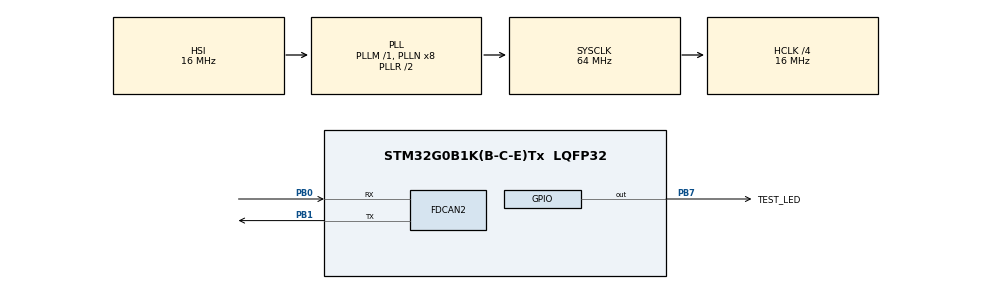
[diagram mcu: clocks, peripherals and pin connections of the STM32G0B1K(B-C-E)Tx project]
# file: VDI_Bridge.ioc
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FDCAN2.AutoRetransmission=DISABLE
FDCAN2.CalculateBaudRateNominal=500000
FDCAN2.CalculateTimeBitNominal=2000
FDCAN2.CalculateTimeQuantumNominal=125.0
FDCAN2.FrameFormat=FDCAN_FRAME_CLASSIC
FDCAN2.NominalPrescaler=2
FDCAN2.NominalTimeSeg1=13
FDCAN2.NominalTimeSeg2=2
Mcu.Family=STM32G0
Mcu.Name=STM32G0B1K(B-C-E)Tx
Mcu.Package=LQFP32
NVIC.TIM16_FDCAN_IT0_IRQn=true\:0\:0\:false\:false\:true\:true\:true\:true
NVIC.TIM1_BRK_UP_TRG_COM_IRQn=true\:0\:0\:false\:false\:true\:true\:true\:true
PA13.Mode=Serial_Wire
PA13.Signal=SYS_SWDIO
PA14-BOOT0.Mode=Serial_Wire
PA14-BOOT0.Signal=SYS_SWCLK
PB0.Mode=FDCAN_Activate
PB0.Signal=FDCAN2_RX
PB1.Mode=FDCAN_Activate
PB1.Signal=FDCAN2_TX
PB7.GPIO_Label=TEST_LED
PB7.Signal=GPIO_Output
ProjectManager.HeapSize=0x200
ProjectManager.StackSize=0x400
ProjectManager.TargetToolchain=STM32CubeIDE
RCC.ADCFreq_Value=64000000
RCC.AHBCLKDivider=RCC_SYSCLK_DIV4
RCC.AHBFreq_Value=16000000
RCC.CortexFreq_Value=16000000
RCC.EXTERNAL_CLOCK_VALUE=48000
RCC.HCLKFreq_Value=16000000
RCC.HSE_VALUE=8000000
RCC.HSI48_VALUE=48000000
RCC.HSI_VALUE=16000000
RCC.LSE_VALUE=32768
RCC.SYSCLKFreq_VALUE=64000000
RCC.SYSCLKSource=RCC_SYSCLKSOURCE_PLLCLK
RCC.USBFreq_Value=48000000
RCC.VCOOutputFreq_Value=128000000
TIM1.Period=100-1
TIM1.Prescaler=16000-1
VP_SYS_VS_DBSignals.Mode=DisableDeadBatterySignals
VP_TIM1_VS_ClockSourceINT.Mode=Internal
board=custom

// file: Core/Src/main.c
/* USER CODE BEGIN Header */
/**
 ******************************************************************************
 * @file           : main.c
 * @brief          : Main program body
 ******************************************************************************
 * @attention
 *
 * Copyright (c) 2024 STMicroelectronics.
 * All rights reserved.
 *
 * This software is licensed under terms that can be found in the LICENSE file
 * in the root directory of this software component.
 * If no LICENSE file comes with this software, it is provided AS-IS.
 *
 ******************************************************************************
 */
/* USER CODE END Header */
#include "main.h"

FDCAN_HandleTypeDef hfdcan2;

TIM_HandleTypeDef htim1;

/* USER CODE BEGIN PV */
uint8_t TxData[CAN_SIZE];
uint8_t TxDataBEAT[CAN_SIZE];
uint8_t TxDataSTART[CAN_SIZE];

uint8_t RxData[CAN_SIZE];
uint32_t TxMailbox;
FDCAN_TxHeaderTypeDef TxHeader;
FDCAN_TxHeaderTypeDef TxHeaderBEAT;
FDCAN_TxHeaderTypeDef TxHeaderSTART;
FDCAN_RxHeaderTypeDef RxHeader;
/* USER CODE END PV */

void SystemClock_Config(void);
static void MX_GPIO_Init(void);
static void MX_FDCAN2_Init(void);
static void MX_TIM1_Init(void);
/* USER CODE BEGIN PFP */
void FDCAN_Send_Bridge_Start();
void FDCAN_Send_Bridge_Command();
/* USER CODE END PFP */

int main(void)
{

  /* MCU Configuration--------------------------------------------------------*/

  /* Reset of all peripherals, Initializes the Flash interface and the Systick. */
  HAL_Init();

  /* Configure the system clock */
  SystemClock_Config();

  /* Initialize all configured peripherals */
  MX_GPIO_Init();
  MX_FDCAN2_Init();
  MX_TIM1_Init();
  /* USER CODE BEGIN 2 */
	HAL_FDCAN_Start(&hfdcan2);
	HAL_FDCAN_ActivateNotification(&hfdcan2, FDCAN_IT_RX_FIFO0_NEW_MESSAGE, 0);
	HAL_Delay(1000); // nach Init von Can, um Startnode zu senden
	FDCAN_Send_Bridge_Start();
	HAL_Delay(100); // nach STartnode warten, um HEARTBEAT zu starten
	HAL_TIM_Base_Start_IT(&htim1);
	HAL_Delay(1000); // Nach starten des HEARTBEAT, warte 1 sekunden bis die Freigabe gesendet wird

  /* USER CODE END 2 */

  /* Infinite loop */
  /* USER CODE BEGIN WHILE */
	while (1) {
		FDCAN_Send_Bridge_Command();
    /* USER CODE END WHILE */

	}
}

void SystemClock_Config(void)
{
  RCC_OscInitTypeDef RCC_OscInitStruct = {0};
  RCC_ClkInitTypeDef RCC_ClkInitStruct = {0};

  /** Configure the main internal regulator output voltage
  */
  HAL_PWREx_ControlVoltageScaling(PWR_REGULATOR_VOLTAGE_SCALE1);

  /** Initializes the RCC Oscillators according to the specified parameters
  * in the RCC_OscInitTypeDef structure.
  */
  RCC_OscInitStruct.OscillatorType = RCC_OSCILLATORTYPE_HSI;
  RCC_OscInitStruct.HSIState = RCC_HSI_ON;
  RCC_OscInitStruct.HSIDiv = RCC_HSI_DIV1;
  RCC_OscInitStruct.HSICalibrationValue = RCC_HSICALIBRATION_DEFAULT;
  RCC_OscInitStruct.PLL.PLLState = RCC_PLL_ON;
  RCC_OscInitStruct.PLL.PLLSource = RCC_PLLSOURCE_HSI;
  RCC_OscInitStruct.PLL.PLLM = RCC_PLLM_DIV1;
  RCC_OscInitStruct.PLL.PLLN = 8;
  RCC_OscInitStruct.PLL.PLLP = RCC_PLLP_DIV2;
  RCC_OscInitStruct.PLL.PLLQ = RCC_PLLQ_DIV2;
  RCC_OscInitStruct.PLL.PLLR = RCC_PLLR_DIV2;
  if (HAL_RCC_OscConfig(&RCC_OscInitStruct) != HAL_OK)
  {
    Error_Handler();
  }

  /** Initializes the CPU, AHB and APB buses clocks
  */
  RCC_ClkInitStruct.ClockType = RCC_CLOCKTYPE_HCLK|RCC_CLOCKTYPE_SYSCLK
                              |RCC_CLOCKTYPE_PCLK1;
  RCC_ClkInitStruct.SYSCLKSource = RCC_SYSCLKSOURCE_PLLCLK;
  RCC_ClkInitStruct.AHBCLKDivider = RCC_SYSCLK_DIV4;
  RCC_ClkInitStruct.APB1CLKDivider = RCC_HCLK_DIV1;

  if (HAL_RCC_ClockConfig(&RCC_ClkInitStruct, FLASH_LATENCY_0) != HAL_OK)
  {
    Error_Handler();
  }
}

static void MX_FDCAN2_Init(void)
{

  hfdcan2.Instance = FDCAN2;
  hfdcan2.Init.ClockDivider = FDCAN_CLOCK_DIV1;
  hfdcan2.Init.FrameFormat = FDCAN_FRAME_CLASSIC;
  hfdcan2.Init.Mode = FDCAN_MODE_NORMAL;
  hfdcan2.Init.AutoRetransmission = DISABLE;
  hfdcan2.Init.TransmitPause = DISABLE;
  hfdcan2.Init.ProtocolException = DISABLE;
  hfdcan2.Init.NominalPrescaler = 2;
  hfdcan2.Init.NominalSyncJumpWidth = 1;
  hfdcan2.Init.NominalTimeSeg1 = 13;
  hfdcan2.Init.NominalTimeSeg2 = 2;
  hfdcan2.Init.DataPrescaler = 1;
  hfdcan2.Init.DataSyncJumpWidth = 1;
  hfdcan2.Init.DataTimeSeg1 = 1;
  hfdcan2.Init.DataTimeSeg2 = 1;
  hfdcan2.Init.StdFiltersNbr = 0;
  hfdcan2.Init.ExtFiltersNbr = 0;
  hfdcan2.Init.TxFifoQueueMode = FDCAN_TX_FIFO_OPERATION;
  if (HAL_FDCAN_Init(&hfdcan2) != HAL_OK)
  {
    Error_Handler();
  }

}

static void MX_TIM1_Init(void)
{

  TIM_ClockConfigTypeDef sClockSourceConfig = {0};
  TIM_MasterConfigTypeDef sMasterConfig = {0};

  htim1.Instance = TIM1;
  htim1.Init.Prescaler = 16000-1;
  htim1.Init.CounterMode = TIM_COUNTERMODE_UP;
  htim1.Init.Period = 100-1;
  htim1.Init.ClockDivision = TIM_CLOCKDIVISION_DIV1;
  htim1.Init.RepetitionCounter = 0;
  htim1.Init.AutoReloadPreload = TIM_AUTORELOAD_PRELOAD_DISABLE;
  if (HAL_TIM_Base_Init(&htim1) != HAL_OK)
  {
    Error_Handler();
  }
  sClockSourceConfig.ClockSource = TIM_CLOCKSOURCE_INTERNAL;
  if (HAL_TIM_ConfigClockSource(&htim1, &sClockSourceConfig) != HAL_OK)
  {
    Error_Handler();
  }
  sMasterConfig.MasterOutputTrigger = TIM_TRGO_RESET;
  sMasterConfig.MasterOutputTrigger2 = TIM_TRGO2_RESET;
  sMasterConfig.MasterSlaveMode = TIM_MASTERSLAVEMODE_DISABLE;
  if (HAL_TIMEx_MasterConfigSynchronization(&htim1, &sMasterConfig) != HAL_OK)
  {
    Error_Handler();
  }

}

static void MX_GPIO_Init(void)
{
  GPIO_InitTypeDef GPIO_InitStruct = {0};

  /* GPIO Ports Clock Enable */
  __HAL_RCC_GPIOB_CLK_ENABLE();
  __HAL_RCC_GPIOA_CLK_ENABLE();

  /*Configure GPIO pin Output Level */
  HAL_GPIO_WritePin(TEST_LED_GPIO_Port, TEST_LED_Pin, GPIO_PIN_RESET);

  /*Configure GPIO pin : TEST_LED_Pin */
  GPIO_InitStruct.Pin = TEST_LED_Pin;
  GPIO_InitStruct.Mode = GPIO_MODE_OUTPUT_PP;
  GPIO_InitStruct.Pull = GPIO_NOPULL;
  GPIO_InitStruct.Speed = GPIO_SPEED_FREQ_LOW;
  HAL_GPIO_Init(TEST_LED_GPIO_Port, &GPIO_InitStruct);

}

/* USER CODE BEGIN 4 */

void HAL_TIM_PeriodElapsedCallback(TIM_HandleTypeDef *htim) {
	FDCAN_Send_Bridge_Heartbeat();
}
/*
 *
 */
void FDCAN_Send_Bridge_Start() {
	//Kommando aufbauen
	TxHeaderSTART.Identifier = VDI_CAN_ID_START;
	TxHeaderSTART.IdType = FDCAN_STANDARD_ID;
	TxHeaderSTART.TxFrameType = FDCAN_DATA_FRAME;
	TxHeaderSTART.DataLength = FDCAN_DLC_BYTES_2;
	TxHeaderSTART.FDFormat = FDCAN_CLASSIC_CAN;

	TxDataSTART[0] = 0x01; // Laut VDI-RICHTLINIEN - Tabelle C4 - Seite 12-13
	TxDataSTART[1] = 0x15; // Laut VDI-RICHTLINIEN - Tabelle C4 - Seite 12-13

// Fragen ob FdCan bereit zum senden, sonst warten, Led Aus
	HAL_FDCAN_AddMessageToTxFifoQ(&hfdcan2, &TxHeaderSTART, TxDataSTART);
	// Kommando senden
}

/*
 *
 */
void FDCAN_Send_Bridge_Command() {

	//Kommando aufbauen
	TxHeader.Identifier = VDI_CAN_ID_LOGIN;
	TxHeader.IdType = FDCAN_STANDARD_ID;
	TxHeader.TxFrameType = FDCAN_DATA_FRAME;
	TxHeader.DataLength = FDCAN_DLC_BYTES_1;
	TxHeader.FDFormat = FDCAN_CLASSIC_CAN;

	TxData[0] = 0x01; // Freigabe: Laut VDI-RICHTLINIEN - Tabelle C4 - Seite 12-13

// Fragen ob FdCan bereit zum senden, sonst warten, Led Aus

	HAL_Delay(100);
	if (HAL_FDCAN_AddMessageToTxFifoQ(&hfdcan2, &TxHeader, TxData) == HAL_OK) {
		// Kommando senden, Led Ein
		HAL_GPIO_WritePin(TEST_LED_GPIO_Port, TEST_LED_Pin, GPIO_PIN_SET);
	} else {
		HAL_GPIO_TogglePin(TEST_LED_GPIO_Port, TEST_LED_Pin);
	}
}

/*
 *
 */
void FDCAN_Send_Bridge_Heartbeat() {
	//Kommando aufbauen
	TxHeaderBEAT.Identifier = VDI_CAN_ID_HEARTBEAT;
	TxHeaderBEAT.IdType = FDCAN_STANDARD_ID;
	TxHeaderBEAT.TxFrameType = FDCAN_DATA_FRAME;
	TxHeaderBEAT.DataLength = FDCAN_DLC_BYTES_1;
	TxHeaderBEAT.FDFormat = FDCAN_CLASSIC_CAN;

	TxDataBEAT[0] = 0x05; // Laut VDI-RICHTLINIEN - Seite 9- CANopen Protokol

// Fragen ob FdCan bereit zum senden, sonst warten, Led Aus
	if (HAL_FDCAN_AddMessageToTxFifoQ(&hfdcan2, &TxHeaderBEAT, TxDataBEAT)
			== HAL_OK) {
		// Kommando senden
	}
}

/* USER CODE END 4 */

void Error_Handler(void)
{
	__disable_irq();
	while (1) {
	}
}
